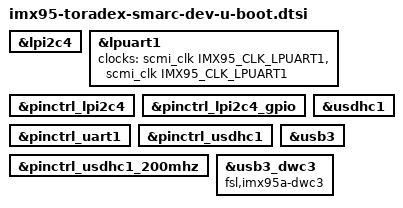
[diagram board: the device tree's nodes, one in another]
// SPDX-License-Identifier: GPL-2.0-or-later OR MIT
/* Copyright (C) 2025 Toradex */

#include "imx95-u-boot.dtsi"

&lpi2c4 {
	bootph-pre-ram;
};

&lpuart1 {
	clocks = <&scmi_clk IMX95_CLK_LPUART1>, <&scmi_clk IMX95_CLK_LPUART1>;
	clock-names = "ipg", "per";
	bootph-pre-ram;
};

&pinctrl_lpi2c4 {
	bootph-pre-ram;
};

&pinctrl_lpi2c4_gpio {
	bootph-pre-ram;
};

&pinctrl_uart1 {
	bootph-pre-ram;
};

&pinctrl_usdhc1 {
	bootph-pre-ram;
};

&pinctrl_usdhc1_200mhz {
	bootph-pre-ram;
};

&usdhc1 {
	bootph-pre-ram;
};

&usb3 {
	/delete-property/power-domains;
};

&usb3_dwc3 {
	compatible = "fsl,imx95a-dwc3", "fsl,imx8mq-dwc3", "snps,dwc3";
};
